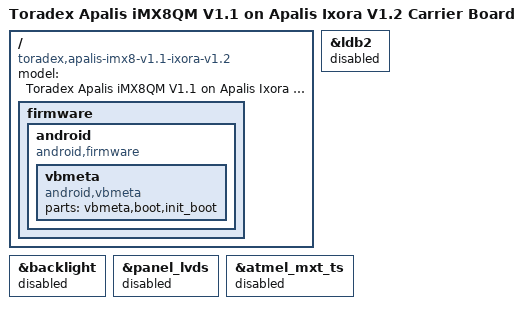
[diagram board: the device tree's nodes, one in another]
// SPDX-License-Identifier: GPL-2.0-or-later OR MIT
/*
 * Copyright 2022 Toradex
 */

/dts-v1/;

#include "imx8qm-apalis-v1.1.dtsi"
#include "imx8-apalis-ixora-v1.2.dtsi"
#include "imx8-apalis-ixora-lvds-10inch.dtsi"

/ {
	model = "Toradex Apalis iMX8QM V1.1 on Apalis Ixora V1.2 Carrier Board";
	compatible = "toradex,apalis-imx8-v1.1-ixora-v1.2",
		     "toradex,apalis-imx8-v1.1",
		     "fsl,imx8qm";

	/* AVB chain used by the Android slot-A installation. */
	firmware {
		android {
			compatible = "android,firmware";
			vbmeta {
				compatible = "android,vbmeta";
				parts = "vbmeta,boot,init_boot";
			};
		};
	};
};

/* Match the validated HDMI-only profile; USB touchscreen is independent. */
&backlight { status = "disabled"; };
&panel_lvds { status = "disabled"; };
&ldb2 { status = "disabled"; };
&atmel_mxt_ts { status = "disabled"; };
